# STC32G144K246 register map
Vendor: STC; File version: 2.0
Registers are 8-bit, read-write, no defined reset value unless marked. A register's access mark holds for its fields unless they carry their own. Offsets are from the block's base; [hi:lo] are bit positions.

## LIN — LIN 共用控制和中断；不访问索引与数据口
Base 0x100000F9
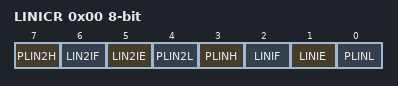
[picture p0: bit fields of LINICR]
0x00 LINICR ro — LINBUS中断控制寄存器
  [7] PLIN2H — 尚未自动匹配到此字段的独立说明；请查看下方章节说明。
  [6] LIN2IF — LIN2 总线中断请求标志位，硬件清零（读取LSR 清零）。 PLIN2H，PLIN2L：LIN2 中断优先级控制位
  [5] LIN2IE — LIN2 总线中断使能控制位
    0=关闭LIN2 中断; 1=使能LIN2 中断
  [4] PLIN2L — 尚未自动匹配到此字段的独立说明；请查看下方章节说明。
  [3] PLINH — 尚未自动匹配到此字段的独立说明；请查看下方章节说明。
  [2] LINIF — LIN 总线中断请求标志位，硬件清零（读取LSR 清零）。 PLINH，PLINL：LIN 中断优先级控制位
  [1] LINIE — LIN 总线中断使能控制位
    0=关闭LIN 中断; 1=使能LIN 中断
  [0] PLINL — 尚未自动匹配到此字段的独立说明；请查看下方章节说明。

## ADC1 — ADC1 通道、触发、时序和转换结果
Base 0x007EFEA8
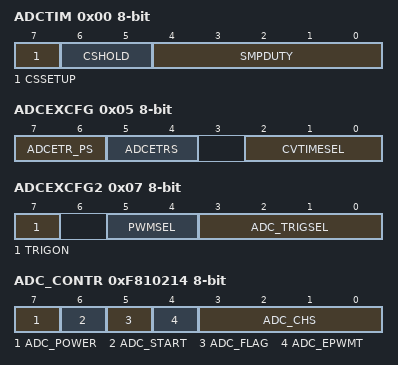
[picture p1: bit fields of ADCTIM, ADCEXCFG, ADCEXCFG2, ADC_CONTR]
0x00 ADCTIM — ADC时序控制寄存器
  [7] CSSETUP — ADC 通道选择时间控制Tsetup
    0=1（默认值）; 1=2
  [6:5] CSHOLD — ADC 通道选择保持时间控制Thold
    0=1; 1=2（默认值）; 2=3; 3=4
  [4:0] SMPDUTY — ADC 模拟信号采样时间控制Tduty（注意：SMPDUTY 一定不能设置小于01010B）
0x05 ADCEXCFG — ADC扩展配置寄存器
  [7:6] ADCETR_PS — ADC 外部触发脚ADC_ETR 功能脚选择
    0=P1.2; 1=P4.3; 2=Value_2; 3=Value_3
  [5:4] ADCETRS — ADC 外部触发脚ADC_ETR 控制位
  [2:0] CVTIMESEL — ADC 自动转换次数选择
0x07 ADCEXCFG2 — ADC扩展配置寄存器2
  [7] TRIGON — 两组ADC 同步触发控制
    0=两组ADC 为各自独立工作模式; 1=两组ADC 为同步模式
  [5:4] PWMSEL — PWM 触发信号配置
  [3:0] ADC_TRIGSEL — 选择ADC 触发源（必须使能ADC_EPWMT，触发源才有效）
    0=PWMA_TA; 1=PWMC_TA; 2=PWME_TA; 3=PWMA_TA2; 4=PWMC_TA2; 5=PWME_TA2; 6=PWMB_TA; 7=PWMD_TA; 8=PWMF_TA; 9=1; 10=0; 11=PWMA_TA; 12=TIMER17 OV; 13=TIMER18 OV; 14=TIMER17 OV phase 180; 15=TIMER18 OV phase 180
0xF810214 ADC_CONTR ro — ADC控制寄存器
  [7] ADC_POWER — ADC 电源控制位
    0=关闭ADC 电源; 1=打开ADC 电源。
  [6] ADC_START — ADC 转换启动控制位。写入1 后开始ADC 转换，转换完成后硬件自动将此位清零。
    0=无影响。即使ADC 已经开始转换工作，写0 也不会停止A/D 转换。; 1=开始ADC 转换，转换完成后硬件自动将此位清零。
  [5] ADC_FLAG — ADC 转换完成中断请求标志。需要软件清零。
  [4] ADC_EPWMT — 使能PWM 实时触发ADC 功能。
  [3:0] ADC_CHS — ADC 模拟通道选择位 （注意：被选择为ADC 输入通道的I/O 口，必须设置PxM0/PxM1 寄存器将I/O 口模式设置为高阻输 入模式。另外如果MCU 进入主时钟停振/省电模式后，仍需要使能ADC 通道，则需要设置PxIE 寄 存器关闭数字输入通道，以防止外部模拟输入信号忽高忽低而产生额外的功
    0=ADC 通道：P1.0；ADC_CHS[3:0]：1000；ADC 通道：P0.0; 1=ADC 通道：P1.1；ADC_CHS[3:0]：1001；ADC 通道：P0.1; 2=ADC 通道：P1.2；ADC_CHS[3:0]：1010；ADC 通道：P0.2; 3=ADC 通道：P1.3；ADC_CHS[3:0]：1011；ADC 通道：OP1O; 4=ADC 通道：P1.4；ADC_CHS[3:0]：1100；ADC 通道：OP2O; 5=ADC 通道：P1.5；ADC_CHS[3:0]：1101；ADC 通道：OP3O; 6=ADC 通道：P1.6；ADC_CHS[3:0]：1110；ADC 通道：OP4O; 7=ADC 通道：P1.7；ADC_CHS[3:0]：1111；ADC 通道：测试内部1.19V
0xF810215 ADC_RES ro — ADC转换结果高位寄存器
  [7:0] ADC_RES — 尚未自动匹配到此字段的独立说明；请查看下方章节说明。
0xF810216 ADC_RESL ro — ADC转换结果低位寄存器
  [7:0] ADC_RESL — 尚未自动匹配到此字段的独立说明；请查看下方章节说明。
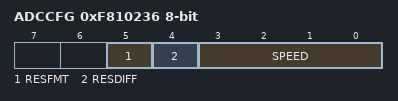
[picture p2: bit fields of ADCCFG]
0xF810236 ADCCFG — ADC配置寄存器
  [5] RESFMT — ADC 转换结果格式控制位
    0=转换结果左对齐。ADC_RES 保存结果的高8 位，ADC_RESL 保存结果的低4 位。格式如下：; 1=转换结果右对齐。ADC_RES 保存结果的高4 位，ADC_RESL 保存结果的低8 位。格式如下：
  [4] RESDIFF — ADC 转换结果为差分格式
    0=非差分格式。ADC_RES[11:0]为原始的ADC 转换结果; 1=差分格式。当ADC1 和ADC2 为同步触发模式时，可将RESDIFF 设置为1，可以模拟出差分通
  [3:0] SPEED — 设置ADC 时钟｛FADC＝SYSclk/2/(SPEED+1)｝

## ADC2 — ADC2 通道、触发、时序和转换结果
Base 0x007EFB38
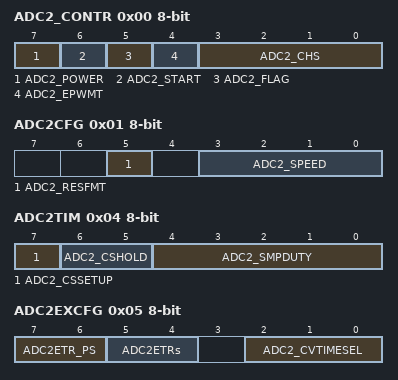
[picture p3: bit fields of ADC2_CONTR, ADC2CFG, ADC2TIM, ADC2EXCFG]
0x00 ADC2_CONTR ro — ADC2控制寄存器
  [7] ADC2_POWER — ADC2 电源控制位
    0=关闭ADC2 电源; 1=打开ADC2 电源。
  [6] ADC2_START — ADC2 转换启动控制位。写入1 后开始ADC2 转换，转换完成后硬件自动将此位清零。
    0=无影响。即使ADC2 已经开始转换工作，写0 也不会停止A/D 转换。; 1=开始ADC2 转换，转换完成后硬件自动将此位清零。
  [5] ADC2_FLAG — ADC2 转换完成中断请求标志。需要软件清零。
  [4] ADC2_EPWMT — 使能PWM 实时触发ADC2 功能
  [3:0] ADC2_CHS — ADC2 模拟通道选择位 （注意：被选择为ADC2 输入通道的I/O 口，必须设置PxM0/PxM1 寄存器将I/O 口模式设置为高阻输 入模式。另外如果MCU 进入主时钟停振/省电模式后，仍需要使能ADC2 通道，则需要设置PxIE 寄存器关闭数字输入通道，以防止外部模拟输入信号忽高忽低而产生额外
    0=ADC2 通道：P0.0；ADC2_CHS[3:0]：1000；ADC2 通道：P6.0; 1=ADC2 通道：P0.1；ADC2_CHS[3:0]：1001；ADC2 通道：P6.1; 2=ADC2 通道：P0.2；ADC2_CHS[3:0]：1010；ADC2 通道：P6.2; 3=ADC2 通道：P0.3；ADC2_CHS[3:0]：1011；ADC2 通道：OP1O; 4=ADC2 通道：P0.4；ADC2_CHS[3:0]：1100；ADC2 通道：OP2O; 5=ADC2 通道：P0.5；ADC2_CHS[3:0]：1101；ADC2 通道：OP3O; 6=ADC2 通道：P0.6；ADC2_CHS[3:0]：1110；ADC2 通道：OP4O; 7=ADC2 通道：P0.7；ADC2_CHS[3:0]：1111；ADC2 通道：测试内部1.19V
0x01 ADC2CFG — ADC2配置寄存器
  [5] ADC2_RESFMT — ADC2 转换结果格式控制位
    0=转换结果左对齐。ADC2_RES 保存结果的高8 位，ADC2_RESL 保存结果的低4 位。格式如下：; 1=转换结果右对齐。ADC2_RES 保存结果的高4 位，ADC2_RESL 保存结果的低8 位。格式如下：
  [3:0] ADC2_SPEED — 设置ADC2 时钟｛FADC2＝SYSclk/2/(ADC2_SPEED+1)｝
0x02 ADC2_RES ro — ADC2转换结果高位寄存器
  [7:0] ADC2_RES — 尚未自动匹配到此字段的独立说明；请查看下方章节说明。
0x03 ADC2_RESL ro — ADC2转换结果低位寄存器
  [7:0] ADC2_RESLADC2 — 尚未自动匹配到此字段的独立说明；请查看下方章节说明。
0x04 ADC2TIM — ADC2时序控制寄存器
  [7] ADC2_CSSETUP — ADC2 通道选择时间控制Tsetup
    0=1（默认值）; 1=2
  [6:5] ADC2_CSHOLD — ADC2 通道选择保持时间控制Thold
    0=1; 1=2（默认值）; 2=3; 3=4
  [4:0] ADC2_SMPDUTY — ADC2模拟信号采样时间控制Tduty（注意：SMPDUTY一定不能设置小于01010B）
0x05 ADC2EXCFG — ADC2扩展配置寄存器
  [7:6] ADC2ETR_PS — ADC2 外部触发脚ADC2_ETR 功能脚选择
    0=P1.2; 1=P4.3; 2=Value_2; 3=Value_3
  [5:4] ADC2ETRs — 尚未自动匹配到此字段的独立说明；请查看下方章节说明。
  [2:0] ADC2_CVTIMESEL — ADC2 自动转换次数选择
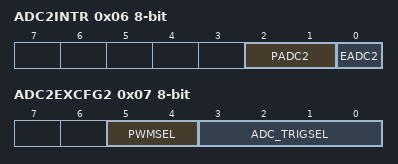
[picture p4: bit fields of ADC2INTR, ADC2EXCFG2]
0x06 ADC2INTR ro — ADC2中断控制寄存器
  [2:1] PADC2 — ADC2 中断优先级控制位
    0=ADC2 中断优先级为0 级（最低级）; 1=ADC2 中断优先级为1 级（较低级）; 2=ADC2 中断优先级为2 级（较高级）; 3=ADC2 中断优先级为3 级（最高级）
  [0] EADC2 — ADC2 中断使能控制位
    0=禁止ADC2 中断; 1=允许ADC2 中断
0x07 ADC2EXCFG2 — ADC2扩展配置寄存器2
  [5:4] PWMSEL — PWM 触发信号配置
  [3:0] ADC_TRIGSEL — 尚未自动匹配到此字段的独立说明；请查看下方章节说明。
